# f29h85x_hsm_soc_ctrl_regs register map
Vendor: Texas Instruments
Peripheral module from a debugger description file (folder HSM).
Registers are 32-bit, read-write, no defined reset value unless marked. A register's access mark holds for its fields unless they carry their own. Offsets are as the file gives them; lines under a group give offsets from that group; [hi:lo] are bit positions; {n}, {i} and the like mark numbered series; 'fields as' and 'values as' point back to an identical list; <NAME> marks a mode.

## HSM_SOC_CTRL — HSM SOC CTRL Registers
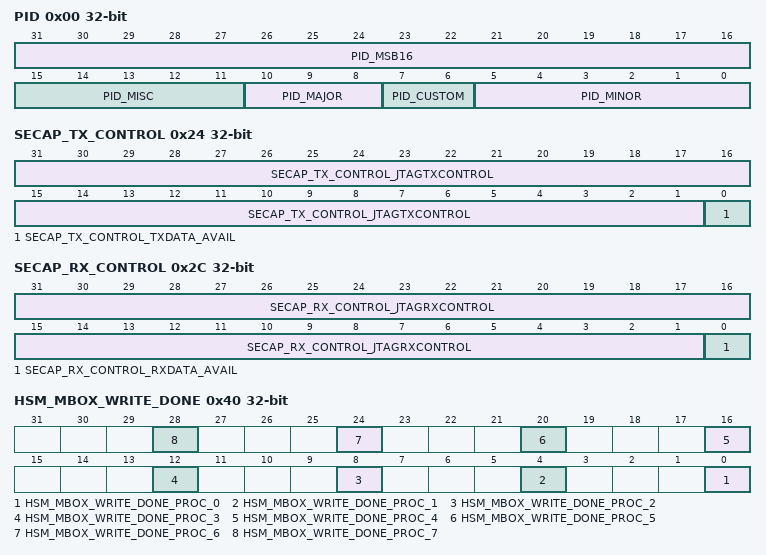
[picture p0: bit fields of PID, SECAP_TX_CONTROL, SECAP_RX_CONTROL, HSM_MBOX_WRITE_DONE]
0x00 PID ro
  [31:16] PID_MSB16, [15:11] PID_MISC, [10:8] PID_MAJOR, [7:6] PID_CUSTOM, [5:0] PID_MINOR
{0x4+4i} HW_REG{i} (i=0..3)
  [31:0] HW_REG{i}_HWREG{i}
0x20 SECAP_TX_DATA ro
  [31:0] SECAP_TX_DATA_JTAGTXDATA
0x24 SECAP_TX_CONTROL ro
  [31:1] SECAP_TX_CONTROL_JTAGTXCONTROL, [0] SECAP_TX_CONTROL_TXDATA_AVAIL
0x28 SECAP_RX_DATA
  [31:0] SECAP_RX_DATA_JTAGRXDATA
0x2C SECAP_RX_CONTROL access per field
  [31:1] SECAP_RX_CONTROL_JTAGRXCONTROL rw, [0] SECAP_RX_CONTROL_RXDATA_AVAIL ro
0x30 HSM_MBOX_MEMINIT_START
  [0] HSM_MBOX_MEMINIT_START_HSM_MBOX_MEMINIT_START
0x34 HSM_MBOX_MEMINIT_STATUS ro
  [0] HSM_MBOX_MEMINIT_STATUS_HSM_MBOX_MEMINIT_STATUS
0x38 HSM_MBOX_MEMINIT_DONE
  [0] HSM_MBOX_MEMINIT_DONE_HSM_MBOX_MEMINIT_DONE
0x40 HSM_MBOX_WRITE_DONE
  [4n] HSM_MBOX_WRITE_DONE_PROC_{n} (n=0..7)
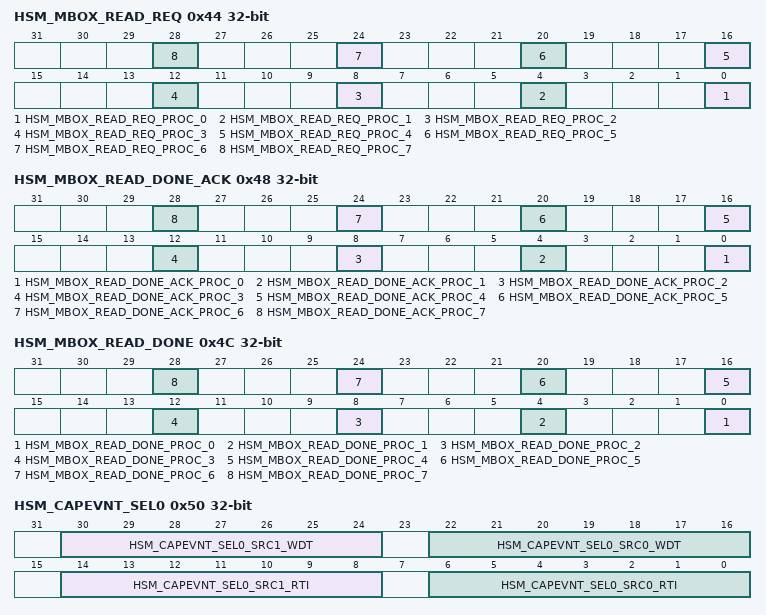
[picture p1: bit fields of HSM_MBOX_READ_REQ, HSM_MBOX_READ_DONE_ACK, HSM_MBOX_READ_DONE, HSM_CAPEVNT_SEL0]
0x44 HSM_MBOX_READ_REQ
  [4n] HSM_MBOX_READ_REQ_PROC_{n} (n=0..7)
0x48 HSM_MBOX_READ_DONE_ACK
  [4n] HSM_MBOX_READ_DONE_ACK_PROC_{n} (n=0..7)
0x4C HSM_MBOX_READ_DONE
  [4n] HSM_MBOX_READ_DONE_PROC_{n} (n=0..7)
0x50 HSM_CAPEVNT_SEL0
  [30:24] HSM_CAPEVNT_SEL0_SRC1_WDT, [22:16] HSM_CAPEVNT_SEL0_SRC0_WDT, [14:8] HSM_CAPEVNT_SEL0_SRC1_RTI, [6:0] HSM_CAPEVNT_SEL0_SRC0_RTI
0x54 HSM_DMA_REQ
  [2:0] HSM_DMA_REQ_SELECT
0x58 HSM_IRQ_REQ
  [3:0] HSM_IRQ_REQ_SELECT
0x5C HSM_ESM_REQ
  [1:0] HSM_ESM_REQ_SELECT
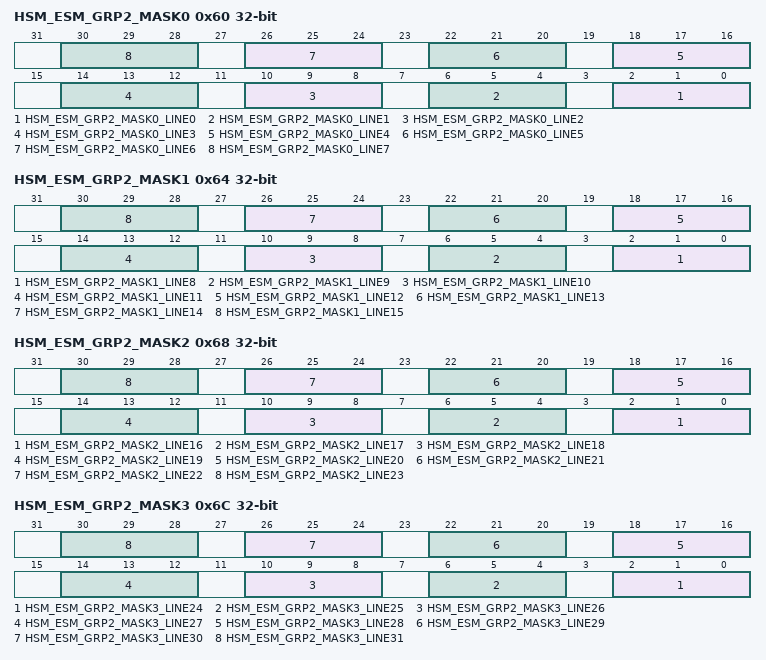
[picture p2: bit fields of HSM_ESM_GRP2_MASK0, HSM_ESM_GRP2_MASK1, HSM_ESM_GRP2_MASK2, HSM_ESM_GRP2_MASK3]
0x60 HSM_ESM_GRP2_MASK0
  [4n+2:4n] HSM_ESM_GRP2_MASK0_LINE{n} (n=0..7)
0x64 HSM_ESM_GRP2_MASK1
  [4n-30:4n-32] HSM_ESM_GRP2_MASK1_LINE{n} (n=8..15)
0x68 HSM_ESM_GRP2_MASK2
  [4n-62:4n-64] HSM_ESM_GRP2_MASK2_LINE{n} (n=16..23)
0x6C HSM_ESM_GRP2_MASK3
  [4n-94:4n-96] HSM_ESM_GRP2_MASK3_LINE{n} (n=24..31)
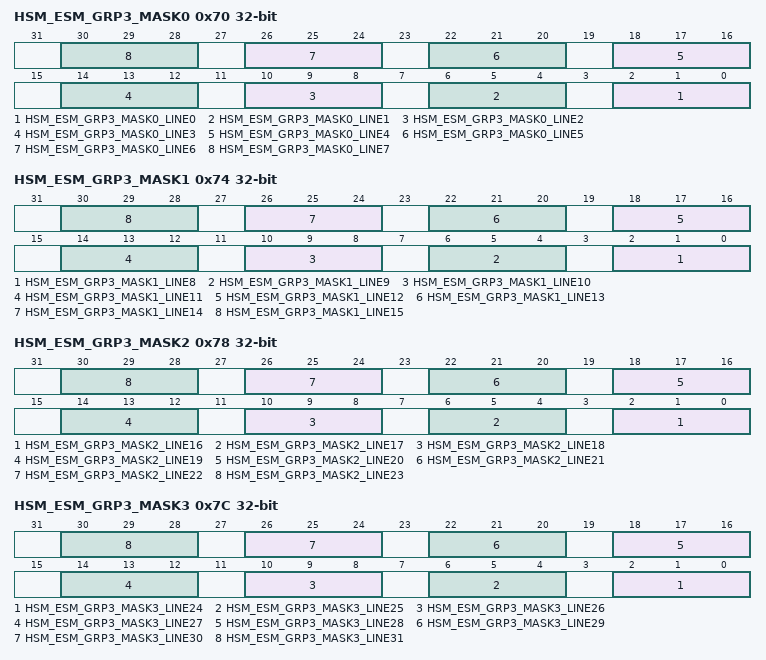
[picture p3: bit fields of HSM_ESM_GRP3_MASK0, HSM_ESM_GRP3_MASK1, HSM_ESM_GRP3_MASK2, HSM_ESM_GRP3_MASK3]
0x70 HSM_ESM_GRP3_MASK0
  [4n+2:4n] HSM_ESM_GRP3_MASK0_LINE{n} (n=0..7)
0x74 HSM_ESM_GRP3_MASK1
  [4n-30:4n-32] HSM_ESM_GRP3_MASK1_LINE{n} (n=8..15)
0x78 HSM_ESM_GRP3_MASK2
  [4n-62:4n-64] HSM_ESM_GRP3_MASK2_LINE{n} (n=16..23)
0x7C HSM_ESM_GRP3_MASK3
  [4n-94:4n-96] HSM_ESM_GRP3_MASK3_LINE{n} (n=24..31)
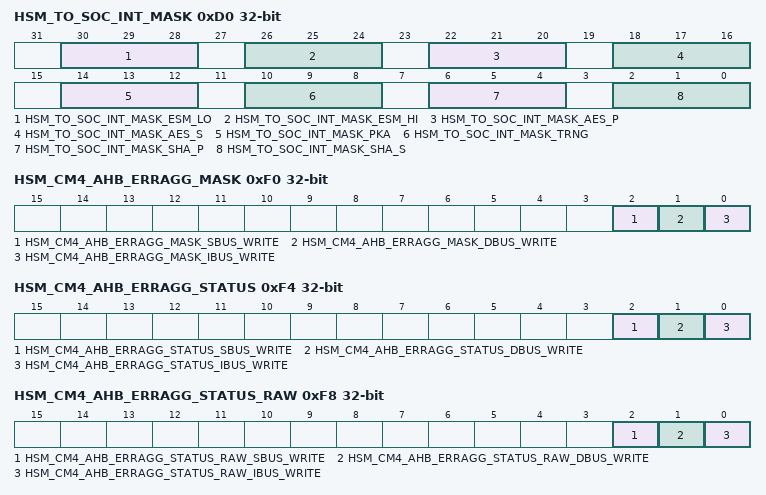
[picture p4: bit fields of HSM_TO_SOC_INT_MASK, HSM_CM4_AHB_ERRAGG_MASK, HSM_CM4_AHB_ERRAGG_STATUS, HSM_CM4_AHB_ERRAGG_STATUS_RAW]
0xD0 HSM_TO_SOC_INT_MASK
  [30:28] HSM_TO_SOC_INT_MASK_ESM_LO, [26:24] HSM_TO_SOC_INT_MASK_ESM_HI, [22:20] HSM_TO_SOC_INT_MASK_AES_P, [18:16] HSM_TO_SOC_INT_MASK_AES_S, [14:12] HSM_TO_SOC_INT_MASK_PKA, [10:8] HSM_TO_SOC_INT_MASK_TRNG, [6:4] HSM_TO_SOC_INT_MASK_SHA_P, [2:0] HSM_TO_SOC_INT_MASK_SHA_S
0xD4 HSM_WDT_RST_CONFIG
  [2:0] HSM_WDT_RST_CONFIG_ENABLE
0xF0 HSM_CM4_AHB_ERRAGG_MASK
  [2] HSM_CM4_AHB_ERRAGG_MASK_SBUS_WRITE, [1] HSM_CM4_AHB_ERRAGG_MASK_DBUS_WRITE, [0] HSM_CM4_AHB_ERRAGG_MASK_IBUS_WRITE
0xF4 HSM_CM4_AHB_ERRAGG_STATUS
  [2] HSM_CM4_AHB_ERRAGG_STATUS_SBUS_WRITE, [1] HSM_CM4_AHB_ERRAGG_STATUS_DBUS_WRITE, [0] HSM_CM4_AHB_ERRAGG_STATUS_IBUS_WRITE
0xF8 HSM_CM4_AHB_ERRAGG_STATUS_RAW
  [2] HSM_CM4_AHB_ERRAGG_STATUS_RAW_SBUS_WRITE, [1] HSM_CM4_AHB_ERRAGG_STATUS_RAW_DBUS_WRITE, [0] HSM_CM4_AHB_ERRAGG_STATUS_RAW_IBUS_WRITE
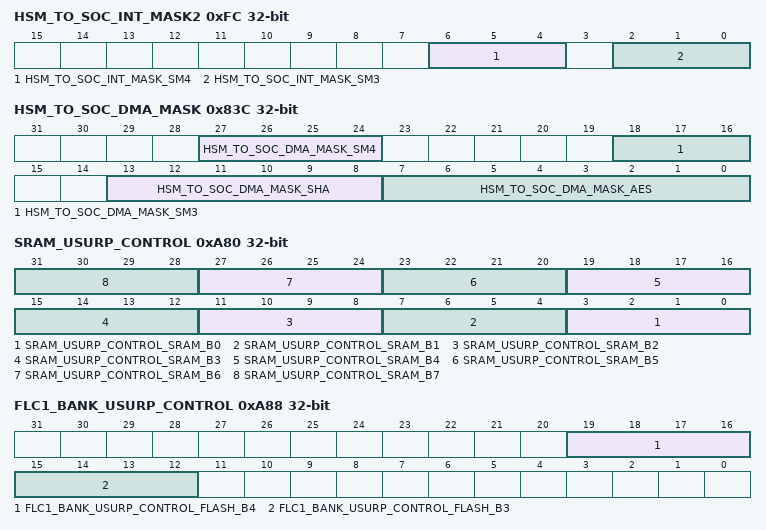
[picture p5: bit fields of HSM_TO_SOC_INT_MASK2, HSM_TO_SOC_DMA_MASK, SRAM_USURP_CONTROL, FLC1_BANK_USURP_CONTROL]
0xFC HSM_TO_SOC_INT_MASK2
  [6:4] HSM_TO_SOC_INT_MASK_SM4, [2:0] HSM_TO_SOC_INT_MASK_SM3
0x100 HSM_APPCPU_RST_CAUSE ro — Host CPU Reset status register. Reset on PORESETn only
  [7:0] HSM_APPCPU_RST_CAUSE_STATUS
0x104 HSM_APPCPU_RST_CAUSE_CLR
  [7:0] HSM_APPCPU_RST_CAUSE_CLR_CLEAR
0x82C HSM_RTC_CFG_CTRL
  [0] HSM_RTC_CFG_CTRL_COUNTER_READ_ENABLE
0x830 HSM_RTC_CFG_STATUS ro
  [0] HSM_RTC_CFG_STATUS_READ_VALID
0x834 HSM_RTC_MSB_COUNTER ro
  [31:0] HSM_RTC_MSB_COUNTER_VALUE
0x838 HSM_RTC_LSB_COUNTER ro
  [31:0] HSM_RTC_LSB_COUNTER_VALUE
0x83C HSM_TO_SOC_DMA_MASK
  [27:24] HSM_TO_SOC_DMA_MASK_SM4, [18:16] HSM_TO_SOC_DMA_MASK_SM3, [13:8] HSM_TO_SOC_DMA_MASK_SHA, [7:0] HSM_TO_SOC_DMA_MASK_AES
0xA80 SRAM_USURP_CONTROL
  [4n+3:4n] SRAM_USURP_CONTROL_SRAM_B{n} (n=0..7)
0xA88 FLC1_BANK_USURP_CONTROL
  [19:16] FLC1_BANK_USURP_CONTROL_FLASH_B4, [15:12] FLC1_BANK_USURP_CONTROL_FLASH_B3
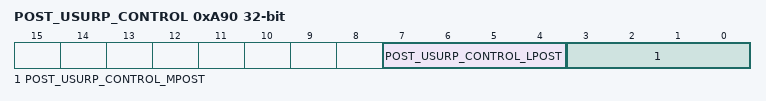
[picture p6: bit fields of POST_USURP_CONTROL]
0xA90 POST_USURP_CONTROL
  [7:4] POST_USURP_CONTROL_LPOST, [3:0] POST_USURP_CONTROL_MPOST
0xA94 SOC_USURP_CONTROL1
  [7:4] SOC_USURP_CONTROL1_CTRL1
0xAC0 HSM_TX_REG0 — HSM to SOC Transmit register 0
  [31:0] HSM_TX_REG0_TX_REG
0xAC4 HSM_TX_REG1 — HSM to SOC Transmit register 1
  [31:0] HSM_TX_REG1_TX_REG
0xAC8 HSM_RX_REG0 ro — SOC to HSM Transmit register 0
  [31:0] HSM_RX_REG0_RX_REG
0xACC HSM_RX_REG1 ro — SOC to HSM Transmit register 1
  [31:0] HSM_RX_REG1_RX_REG
0xAD0 HSM_SOCACC_ERROR_TYPE ro — Error status of HSM to SOC Access
  [15:0] HSM_SOCACC_ERROR_TYPE_STATUS
0xAD4 HSM_SOCACC_ERROR_ADDR ro — Error Address of HSM to SOC Access
  [31:0] HSM_SOCACC_ERROR_ADDR_STATUS
0xAD8 HSM_SOCACC_ERROR_CLR
  [0] HSM_SOCACC_ERROR_CLR_CLEAR
0x1008 LOCK0_KICK0 — Lock register for HSM_CTRL and HSM_SOC_CTRL registers.
0x100C LOCK0_KICK1 — Unlock register for HSM_CTRL and HSM_SOC_CTRL registers.
